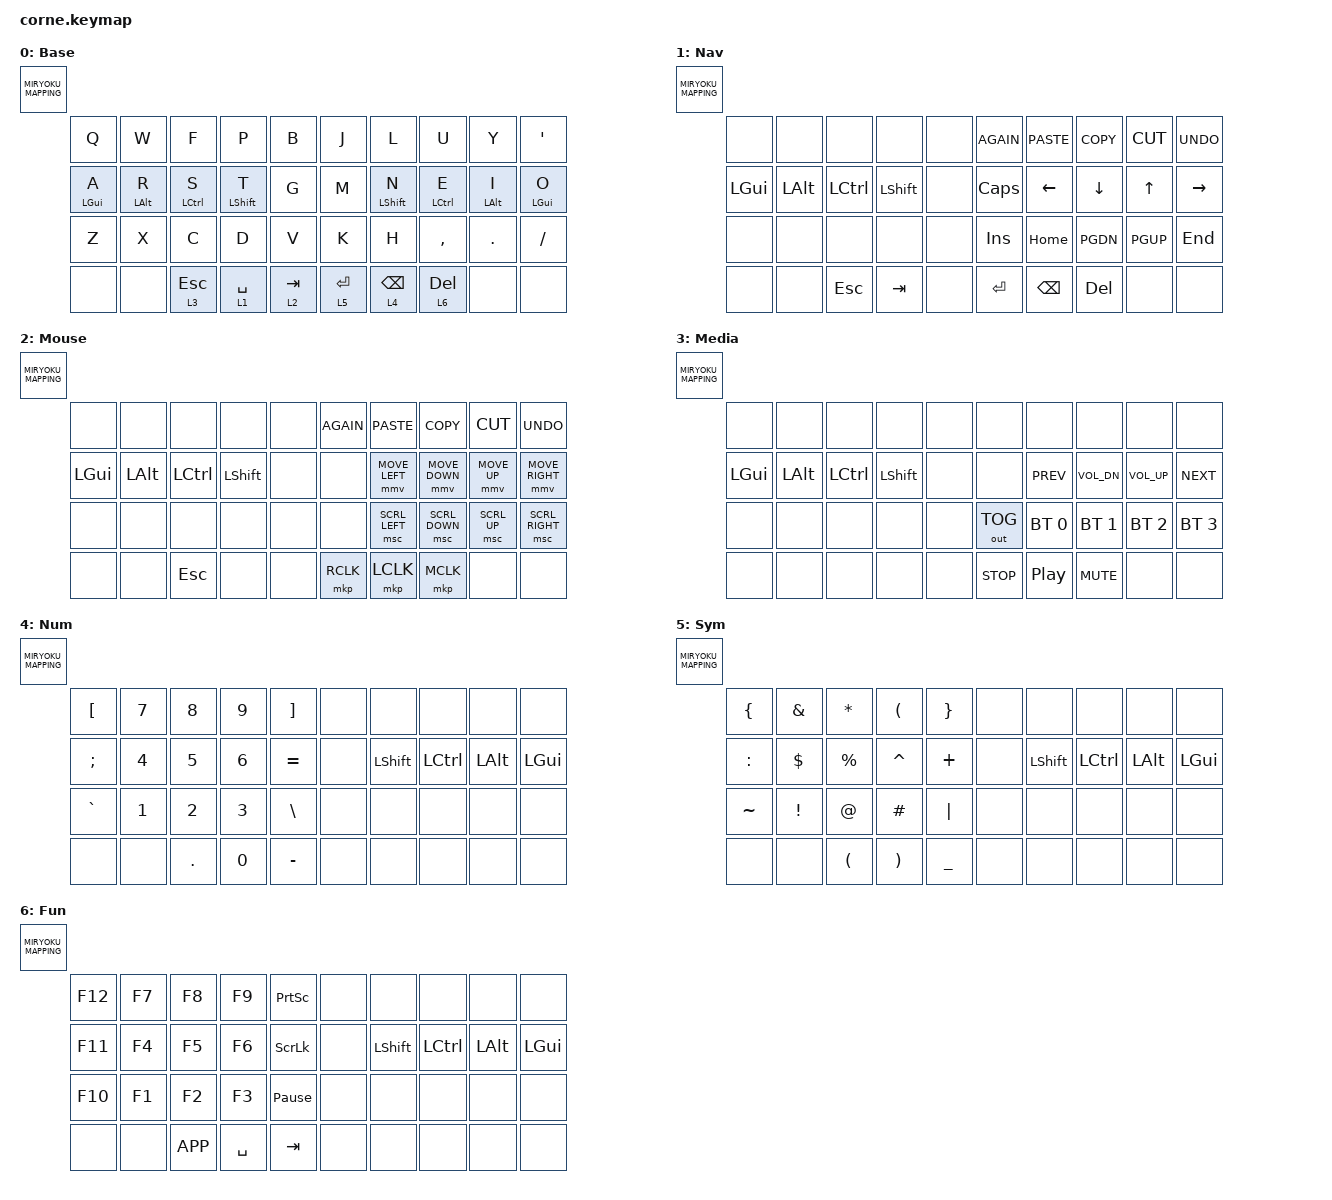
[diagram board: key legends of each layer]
#include <behaviors.dtsi>
#include <dt-bindings/zmk/keys.h>
#include <dt-bindings/zmk/bt.h>
#include <dt-bindings/zmk/outputs.h>
#include <dt-bindings/zmk/pointing.h>

/* Miryoku Core Behaviors */
/ {
    behaviors {
        u_mt: u_mt {
            compatible = "zmk,behavior-hold-tap";
            #binding-cells = <2>;
            tapping-term-ms = <200>;
            flavor = "tap-preferred";
            bindings = <&kp>, <&kp>;
        };
        u_lt: u_lt {
            compatible = "zmk,behavior-hold-tap";
            #binding-cells = <2>;
            tapping-term-ms = <200>;
            flavor = "tap-preferred";
            bindings = <&mo>, <&kp>;
        };
    };
};

/* Miryoku 42-key (Corne) Mapping Macro */
#define MIRYOKU_MAPPING( \
    K00, K01, K02, K03, K04,      K05, K06, K07, K08, K09, \
    K10, K11, K12, K13, K14,      K15, K16, K17, K18, K19, \
    K20, K21, K22, K23, K24,      K25, K26, K27, K28, K29, \
    N30, N31, K32, K33, K34,      K35, K36, K37, N38, N39 \
) \
&none  K00  K01  K02  K03  K04       K05  K06  K07  K08  K09  &none \
&none  K10  K11  K12  K13  K14       K15  K16  K17  K18  K19  &none \
&none  K20  K21  K22  K23  K24       K25  K26  K27  K28  K29  &none \
                 K32  K33  K34       K35  K36  K37

/ {
    keymap {
        compatible = "zmk,keymap";

        base_layer {
            display-name = "Base";
            bindings = <MIRYOKU_MAPPING(
                &kp Q,      &kp W,      &kp F,       &kp P,       &kp B,         &kp J,        &kp L,       &kp U,       &kp Y,      &kp SQT,
                &u_mt LGUI A, &u_mt LALT R, &u_mt LCTRL S, &u_mt LSHFT T, &kp G,         &kp M,        &u_mt LSHFT N, &u_mt LCTRL E, &u_mt LALT I, &u_mt LGUI O,
                &kp Z,      &kp X,      &kp C,       &kp D,       &kp V,         &kp K,        &kp H,       &kp COMMA,   &kp DOT,    &kp FSLH,
                &none, &none, &u_lt 3 ESC, &u_lt 1 SPACE, &u_lt 2 TAB,             &u_lt 5 RET, &u_lt 4 BSPC, &u_lt 6 DEL, &none, &none
            )>;
        };

        nav_layer {
            display-name = "Nav";
            bindings = <MIRYOKU_MAPPING(
                &none,      &none,      &none,       &none,       &none,         &kp K_AGAIN,  &kp K_PASTE, &kp K_COPY,  &kp K_CUT,  &kp K_UNDO,
                &kp LGUI,   &kp LALT,   &kp LCTRL,   &kp LSHFT,   &none,         &kp CAPS,     &kp LEFT,    &kp DOWN,    &kp UP,     &kp RIGHT,
                &none,      &none,      &none,       &none,       &none,         &kp INS,      &kp HOME,    &kp PGDN,    &kp PGUP,   &kp END,
                &none, &none, &kp ESC,    &kp TAB,     &none,                 &kp RET,      &kp BSPC,    &kp DEL,     &none, &none
            )>;
        };

        mouse_layer {
            display-name = "Mouse";
            bindings = <MIRYOKU_MAPPING(
                &none,      &none,      &none,       &none,       &none,         &kp K_AGAIN,  &kp K_PASTE, &kp K_COPY,  &kp K_CUT,  &kp K_UNDO,
                &kp LGUI,   &kp LALT,   &kp LCTRL,   &kp LSHFT,   &none,         &none,        &mmv MOVE_LEFT, &mmv MOVE_DOWN, &mmv MOVE_UP, &mmv MOVE_RIGHT,
                &none,      &none,      &none,       &none,       &none,         &none,        &msc SCRL_LEFT, &msc SCRL_DOWN, &msc SCRL_UP, &msc SCRL_RIGHT,
                &none, &none, &kp ESC,    &none,       &none,                 &mkp RCLK,    &mkp LCLK,   &mkp MCLK,   &none, &none
            )>;
        };

        media_layer {
            display-name = "Media";
            bindings = <MIRYOKU_MAPPING(
                &none,      &none,      &none,       &none,       &none,         &none,        &none,       &none,       &none,      &none,
                &kp LGUI,   &kp LALT,   &kp LCTRL,   &kp LSHFT,   &none,         &none,        &kp C_PREV,  &kp C_VOL_DN, &kp C_VOL_UP, &kp C_NEXT,
                &none,      &none,      &none,       &none,       &none,         &out OUT_TOG, &bt BT_SEL 0, &bt BT_SEL 1, &bt BT_SEL 2, &bt BT_SEL 3,
                &none, &none, &none,      &none,       &none,                 &kp C_STOP,   &kp C_PP,    &kp C_MUTE,  &none, &none
            )>;
        };

        num_layer {
            display-name = "Num";
            bindings = <MIRYOKU_MAPPING(
                &kp LBKT,   &kp N7,     &kp N8,      &kp N9,      &kp RBKT,      &none,        &none,       &none,       &none,      &none,
                &kp SEMI,   &kp N4,     &kp N5,      &kp N6,      &kp EQUAL,     &none,        &kp LSHFT,   &kp LCTRL,   &kp LALT,   &kp LGUI,
                &kp GRAVE,  &kp N1,     &kp N2,      &kp N3,      &kp BSLH,      &none,        &none,       &none,       &none,      &none,
                &none, &none, &kp DOT,    &kp N0,      &kp MINUS,             &none,        &none,       &none,       &none, &none
            )>;
        };

        sym_layer {
            display-name = "Sym";
            bindings = <MIRYOKU_MAPPING(
                &kp LBRC,   &kp AMPS,   &kp ASTRK,   &kp LPAR,    &kp RBRC,      &none,        &none,       &none,       &none,      &none,
                &kp COLON,  &kp DLLR,   &kp PRCNT,   &kp CARET,   &kp PLUS,      &none,        &kp LSHFT,   &kp LCTRL,   &kp LALT,   &kp LGUI,
                &kp TILDE,  &kp EXCL,   &kp AT,      &kp HASH,    &kp PIPE,      &none,        &none,       &none,       &none,      &none,
                &none, &none, &kp LPAR,   &kp RPAR,    &kp UNDER,             &none,        &none,       &none,       &none, &none
            )>;
        };

        fun_layer {
            display-name = "Fun";
            bindings = <MIRYOKU_MAPPING(
                &kp F12,    &kp F7,     &kp F8,      &kp F9,      &kp PSCRN,     &none,        &none,       &none,       &none,      &none,
                &kp F11,    &kp F4,     &kp F5,      &kp F6,      &kp SLCK,      &none,        &kp LSHFT,   &kp LCTRL,   &kp LALT,   &kp LGUI,
                &kp F10,    &kp F1,     &kp F2,      &kp F3,      &kp PAUSE_BREAK, &none,      &none,       &none,       &none,      &none,
                &none, &none, &kp K_APP,  &kp SPACE,   &kp TAB,               &none,        &none,       &none,       &none, &none
            )>;
        };
    };
};
